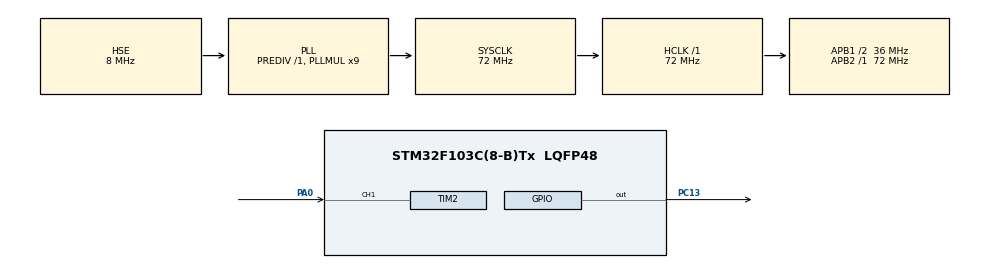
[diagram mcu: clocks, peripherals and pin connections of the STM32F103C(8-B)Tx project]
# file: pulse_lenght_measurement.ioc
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Mcu.Family=STM32F1
Mcu.Name=STM32F103C(8-B)Tx
Mcu.Package=LQFP48
NVIC.PriorityGroup=NVIC_PRIORITYGROUP_4
NVIC.TIM2_IRQn=true\:0\:0\:false\:false\:true\:true\:true
PA0-WKUP.GPIO_PuPd=GPIO_NOPULL
PA0-WKUP.Signal=S_TIM2_CH1_ETR
PA13.Mode=Serial_Wire
PA13.Signal=SYS_JTMS-SWDIO
PA14.Mode=Serial_Wire
PA14.Signal=SYS_JTCK-SWCLK
PC13-TAMPER-RTC.Signal=GPIO_Output
PD0-OSC_IN.Mode=HSE-External-Oscillator
PD0-OSC_IN.Signal=RCC_OSC_IN
PD1-OSC_OUT.Mode=HSE-External-Oscillator
PD1-OSC_OUT.Signal=RCC_OSC_OUT
ProjectManager.HeapSize=0x200
ProjectManager.StackSize=0x400
ProjectManager.TargetToolchain=MDK-ARM V5
RCC.AHBFreq_Value=72000000
RCC.APB1CLKDivider=RCC_HCLK_DIV2
RCC.APB1Freq_Value=36000000
RCC.APB1TimFreq_Value=72000000
RCC.APB2Freq_Value=72000000
RCC.APB2TimFreq_Value=72000000
RCC.HCLKFreq_Value=72000000
RCC.PLLMUL=RCC_PLL_MUL9
RCC.PLLSourceVirtual=RCC_PLLSOURCE_HSE
RCC.SYSCLKFreq_VALUE=72000000
RCC.SYSCLKSource=RCC_SYSCLKSOURCE_PLLCLK
RCC.USBFreq_Value=72000000
SH.S_TIM2_CH1_ETR.0=TIM2_CH1,Input_Capture1_from_TI1
TIM2.AutoReloadPreload=TIM_AUTORELOAD_PRELOAD_ENABLE
TIM2.Channel-Input_Capture1_from_TI1=TIM_CHANNEL_1
TIM2.ICFilter_CH1=0
TIM2.Period=65535
TIM2.Prescaler=143
VP_TIM2_VS_ClockSourceINT.Mode=Internal
board=custom

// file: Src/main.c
/* USER CODE BEGIN Header */
/**
  ******************************************************************************
  * @file           : main.c
  * @brief          : Main program body
  ******************************************************************************
  * @attention
  *
  * <h2><center>&copy; Copyright (c) 2020 STMicroelectronics.
  * All rights reserved.</center></h2>
  *
  * This software component is licensed by ST under BSD 3-Clause license,
  * the "License"; You may not use this file except in compliance with the
  * License. You may obtain a copy of the License at:
  *                        opensource.org/licenses/BSD-3-Clause
  *
  ******************************************************************************
  */
/* USER CODE END Header */

#include "main.h"

TIM_HandleTypeDef htim2;

/* USER CODE BEGIN PV */
uint32_t IC_val1 = 0;
uint32_t IC_val2 = 0;
uint32_t Difference = 0;
uint8_t Is_First_Capture = 0;		//is the first value captured?

/* USER CODE END PV */

void SystemClock_Config(void);
static void MX_GPIO_Init(void);
static void MX_TIM2_Init(void);

/* USER CODE BEGIN 0 */
void HAL_TIM_IC_CaptureCallback(TIM_HandleTypeDef *htim)
{
	if(htim -> Channel == HAL_TIM_ACTIVE_CHANNEL_1)		//if the interrupt source is channel1
	{
		__HAL_TIM_SET_COUNTER(&htim2, 0);     //reset counter sau khi ngat interrupt capture
		if(Is_First_Capture == 0)						  //if the first value is not capture
		{
      IC_val1 = HAL_TIM_ReadCapturedValue(htim, TIM_CHANNEL_1);   //read the first value
      Is_First_Capture = 1;   //set the first capture as true
      //Now change the polarity to falling edge
      __HAL_TIM_SET_CAPTUREPOLARITY(htim, TIM_CHANNEL_1, TIM_INPUTCHANNELPOLARITY_FALLING);
		}
    else if (Is_First_Capture == 1)   //if the first is already capture
    {
      IC_val2 = HAL_TIM_ReadCapturedValue(htim, TIM_CHANNEL_1);   //read second value
      __HAL_TIM_SET_COUNTER(htim, 0);   //reset counter

      if(IC_val2 > IC_val1)
      {
        Difference = IC_val2 - IC_val1;
      }

      Is_First_Capture = 0;   //set it back to false
      //set polarity to rising edge
      __HAL_TIM_SET_CAPTUREPOLARITY(htim, TIM_CHANNEL_1, TIM_INPUTCHANNELPOLARITY_RISING);
    }
	}
}

/* USER CODE END 0 */

int main(void)
{

  /* MCU Configuration--------------------------------------------------------*/

  /* Reset of all peripherals, Initializes the Flash interface and the Systick. */
  HAL_Init();

  /* Configure the system clock */
  SystemClock_Config();

  /* Initialize all configured peripherals */
  MX_GPIO_Init();
  MX_TIM2_Init();
  /* USER CODE BEGIN 2 */
//  __HAL_TIM_SET_CAPTUREPOLARITY(&htim2, TIM_CHANNEL_1, TIM_INPUTCHANNELPOLARITY_BOTHEDGE);
	HAL_TIM_IC_Start_IT(&htim2, TIM_CHANNEL_1);

  /* USER CODE END 2 */

  /* Infinite loop */
  /* USER CODE BEGIN WHILE */
  while (1)
  {
    HAL_GPIO_WritePin(GPIOC, GPIO_PIN_13, GPIO_PIN_RESET);
    HAL_Delay(10);
    HAL_GPIO_WritePin(GPIOC, GPIO_PIN_13, GPIO_PIN_RESET);
    HAL_Delay(10);
    /* USER CODE END WHILE */

  }
}

void SystemClock_Config(void)
{
  RCC_OscInitTypeDef RCC_OscInitStruct = {0};
  RCC_ClkInitTypeDef RCC_ClkInitStruct = {0};

  /** Initializes the CPU, AHB and APB busses clocks
  */
  RCC_OscInitStruct.OscillatorType = RCC_OSCILLATORTYPE_HSE;
  RCC_OscInitStruct.HSEState = RCC_HSE_ON;
  RCC_OscInitStruct.HSEPredivValue = RCC_HSE_PREDIV_DIV1;
  RCC_OscInitStruct.HSIState = RCC_HSI_ON;
  RCC_OscInitStruct.PLL.PLLState = RCC_PLL_ON;
  RCC_OscInitStruct.PLL.PLLSource = RCC_PLLSOURCE_HSE;
  RCC_OscInitStruct.PLL.PLLMUL = RCC_PLL_MUL9;
  if (HAL_RCC_OscConfig(&RCC_OscInitStruct) != HAL_OK)
  {
    Error_Handler();
  }
  /** Initializes the CPU, AHB and APB busses clocks
  */
  RCC_ClkInitStruct.ClockType = RCC_CLOCKTYPE_HCLK|RCC_CLOCKTYPE_SYSCLK
                              |RCC_CLOCKTYPE_PCLK1|RCC_CLOCKTYPE_PCLK2;
  RCC_ClkInitStruct.SYSCLKSource = RCC_SYSCLKSOURCE_PLLCLK;
  RCC_ClkInitStruct.AHBCLKDivider = RCC_SYSCLK_DIV1;
  RCC_ClkInitStruct.APB1CLKDivider = RCC_HCLK_DIV2;
  RCC_ClkInitStruct.APB2CLKDivider = RCC_HCLK_DIV1;

  if (HAL_RCC_ClockConfig(&RCC_ClkInitStruct, FLASH_LATENCY_2) != HAL_OK)
  {
    Error_Handler();
  }
}

static void MX_TIM2_Init(void)
{

  TIM_ClockConfigTypeDef sClockSourceConfig = {0};
  TIM_MasterConfigTypeDef sMasterConfig = {0};
  TIM_IC_InitTypeDef sConfigIC = {0};

  htim2.Instance = TIM2;
  htim2.Init.Prescaler = 143;
  htim2.Init.CounterMode = TIM_COUNTERMODE_UP;
  htim2.Init.Period = 65535;
  htim2.Init.ClockDivision = TIM_CLOCKDIVISION_DIV1;
  htim2.Init.AutoReloadPreload = TIM_AUTORELOAD_PRELOAD_ENABLE;
  if (HAL_TIM_Base_Init(&htim2) != HAL_OK)
  {
    Error_Handler();
  }
  sClockSourceConfig.ClockSource = TIM_CLOCKSOURCE_INTERNAL;
  if (HAL_TIM_ConfigClockSource(&htim2, &sClockSourceConfig) != HAL_OK)
  {
    Error_Handler();
  }
  if (HAL_TIM_IC_Init(&htim2) != HAL_OK)
  {
    Error_Handler();
  }
  sMasterConfig.MasterOutputTrigger = TIM_TRGO_RESET;
  sMasterConfig.MasterSlaveMode = TIM_MASTERSLAVEMODE_DISABLE;
  if (HAL_TIMEx_MasterConfigSynchronization(&htim2, &sMasterConfig) != HAL_OK)
  {
    Error_Handler();
  }
  sConfigIC.ICPolarity = TIM_INPUTCHANNELPOLARITY_RISING;
  sConfigIC.ICSelection = TIM_ICSELECTION_DIRECTTI;
  sConfigIC.ICPrescaler = TIM_ICPSC_DIV1;
  sConfigIC.ICFilter = 0;
  if (HAL_TIM_IC_ConfigChannel(&htim2, &sConfigIC, TIM_CHANNEL_1) != HAL_OK)
  {
    Error_Handler();
  }

}

static void MX_GPIO_Init(void)
{
  GPIO_InitTypeDef GPIO_InitStruct = {0};

  /* GPIO Ports Clock Enable */
  __HAL_RCC_GPIOC_CLK_ENABLE();
  __HAL_RCC_GPIOD_CLK_ENABLE();
  __HAL_RCC_GPIOA_CLK_ENABLE();

  /*Configure GPIO pin Output Level */
  HAL_GPIO_WritePin(GPIOC, GPIO_PIN_13, GPIO_PIN_RESET);

  /*Configure GPIO pin : PC13 */
  GPIO_InitStruct.Pin = GPIO_PIN_13;
  GPIO_InitStruct.Mode = GPIO_MODE_OUTPUT_PP;
  GPIO_InitStruct.Pull = GPIO_NOPULL;
  GPIO_InitStruct.Speed = GPIO_SPEED_FREQ_LOW;
  HAL_GPIO_Init(GPIOC, &GPIO_InitStruct);

}

void Error_Handler(void)
{
}

/************************ (C) COPYRIGHT STMicroelectronics *****END OF FILE****/
